# PIC16F527 register map
Vendor: Microchip
Architecture 16c5x. Special function registers and configuration words.
Registers are 8-bit, read-write, no defined reset value unless marked. A register's access mark holds for its fields unless they carry their own. Addresses are absolute, and some are shared; only a register's first bit layout is shown; lines under a group give offsets from that group; [hi:lo] are bit positions; {n}, {i} and the like mark numbered series; 'fields as' and 'values as' point back to an identical list; <NAME> marks a mode.

## Further device data
pins=1: VDD; 2: RA5/OSC1/CLKIN; 3: RA4/AN3/OSC2/CLKOUT; 4: VPP/MCLR/RA3; 5: RC5; 6: RC4/C2OUT; 7: RC3/AN7/OP1; 8: RC6/OP1-; 9: RC7/OP1+; 10: RB7; 11: RB6; 12: RB5/OP2+; 13: RB4/OP2-; 14: RC2/AN6/OP2; 15: RC1/AN5/C2IN-; 16: RC0/AN4/C2IN+; 17: RA2/AN2/C1OUT/T0CKI; 18: RA1/AN1/C1IN-/CVREF/ICSPCLK; 19: RA0/AN0/C1IN+/ICSPDAT; 20: VSS

## SFR
0x00 INDF access not given
0x01 TMR0 — (power-on value xxxxxxxx)
0x02 PCL reset 0xFF
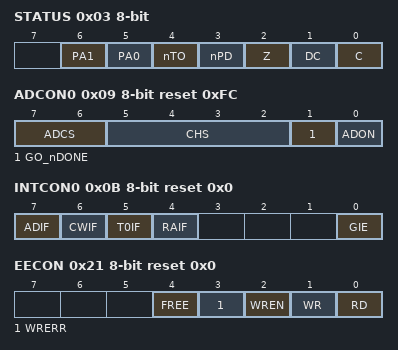
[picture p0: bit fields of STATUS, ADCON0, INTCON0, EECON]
0x03 STATUS — (power-on value -0011xxx)
  [6] PA1, [5] PA0, [4] nTO, [3] nPD, [2] Z, [1] DC, [0] C
0x04 FSR — (power-on value 0xxxxxxx)
  [6:0] FSR
0x05 OSCCAL reset 0xFE
  [7:1] CAL
0x06 PORTA — (power-on value --xxxxxx)
  [5:0] RA
0x07 PORTB — (power-on value xxxx----)
  [7:4] RB
0x08 PORTC — (power-on value xxxxxxxx)
  [7:0] RC
0x09 ADCON0 reset 0xFC
  [7:6] ADCS, [5:2] CHS, [1] GO_nDONE, [0] ADON
0x0A ADRES — (power-on value xxxxxxxx)
0x0B INTCON0 reset 0x0
  [7] ADIF, [6] CWIF, [5] T0IF, [4] RAIF, [0] GIE
0x21 EECON reset 0x0
  [4] FREE
  [3] WRERR
  [2] WREN
  [1] WR — (can only be set)
  [0] RD — (can only be set)
0x25 EEDATA — (power-on value xxxxxxxx)
0x26 EEADR — (power-on value --xxxxxx)
  [5:0] EEADR
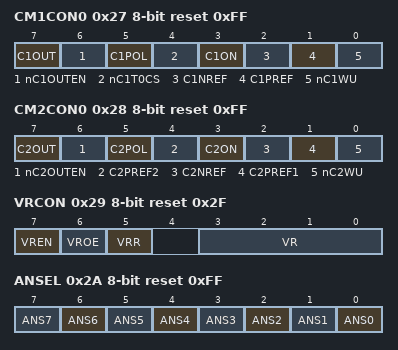
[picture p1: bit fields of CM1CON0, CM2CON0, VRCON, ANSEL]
0x27 CM1CON0 reset 0xFF
  [7] C1OUT ro, [6] nC1OUTEN, [5] C1POL, [4] nC1T0CS, [3] C1ON, [2] C1NREF, [1] C1PREF, [0] nC1WU
0x28 CM2CON0 reset 0xFF
  [7] C2OUT ro, [6] nC2OUTEN, [5] C2POL, [4] C2PREF2, [3] C2ON, [2] C2NREF, [1] C2PREF1, [0] nC2WU
0x29 VRCON reset 0x2F
  [7] VREN, [6] VROE, [5] VRR, [3:0] VR
0x2A ANSEL reset 0xFF
  [n] ANS{n} (n=0..7)
0x61 IW — (power-on value qqqqqqqq)
  [7:0] IWREG
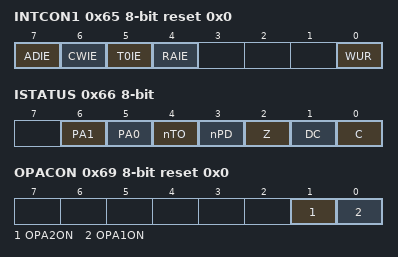
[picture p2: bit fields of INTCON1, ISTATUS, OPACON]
0x65 INTCON1 reset 0x0
  [7] ADIE, [6] CWIE, [5] T0IE, [4] RAIE, [0] WUR
0x66 ISTATUS — (power-on value -0011xxx)
  [6] PA1, [5] PA0, [4] nTO, [3] nPD, [2] Z, [1] DC, [0] C
0x67 IFSR — (power-on value 0xxxxxxx)
  [6:0] IFSR
0x68 IBSR reset 0x0
  [1:0] IBSR
0x69 OPACON reset 0x0
  [1] OPA2ON, [0] OPA1ON

## CONFIG — Configuration words, addresses in ProgramSpace
0xFFF CONFIG 10-bit reset 0x3FF
  [9] DRTEN — Device Reset Timer Enable
    1=ON (DRT Enabled (18 ms)); 0=OFF (DRT Disabled)
  [8] BOREN — Brown-out Reset Enable
    1=ON (BOR Enabled); 0=OFF (BOR Disabled)
  [7] CPSW — Code Protection - Self Writable Memory
    1=OFF (Code protection off); 0=ON (Code protection on)
  [6] IOSCFS — Internal Oscillator Frequency Select
    1=8 MHz INTOSC Speed; 0=4 MHz INTOSC Speed
  [5] MCLRE — Master Clear Enable
    1=ON (MCLR pin functions as MCLR); 0=OFF (MCLR pin functions as I/O, MCLR internally tied to Vdd)
  [4] CP — Code Protection - User Program Memory
    1=OFF (Code protection off); 0=ON (Code protection on)
  [3] WDTE — Watchdog Timer Enable
    1=ON (WDT Enabled); 0=OFF (WDT Disabled)
  [2:0] FOSC — Oscillator Selection
    0=LP (LP oscillator and automatic 18 ms DRT (DRTEN ignored)); 1=XT (XT oscillator and automatic 18 ms DRT (DRTEN ignored)); 2=HS (HS oscillator and automatic 18 ms DRT (DRTEN ignored)); 3=EC (EC oscillator with I/O function on OSC2/CLKOUT and 10 us startup time); 4=INTRC_IO (INTRC with I/O function on OSC2/CLKOUT and 10 us startup time); 5=INTRC_CLKOUT (INTRC with CLKOUT function on OSC2/CLKOUT and 10 us startup time); 6=EXTRC_IO (EXTRC with I/O function on OSC2/CLKOUT and 10 us startup time); 7=EXTRC_CLKOUT (EXTRC with CLKOUT function on OSC2/CLKOUT and 10 us startup time)
